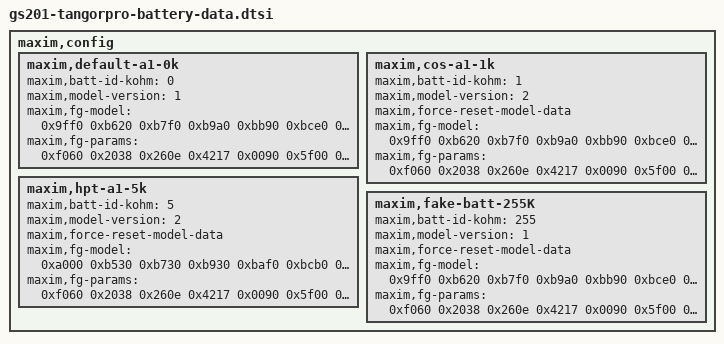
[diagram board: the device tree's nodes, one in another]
// SPDX-License-Identifier: GPL-2.0-only
/*
 * Battery device tree entries
 *
 * Copyright 2022 Google LLC
 *
 */

maxim,config {
	maxim,default-a1-0k {
		maxim,batt-id-kohm = <0>;
		maxim,model-version = <1>;
		maxim,fg-model = /bits/ 16 <
			0x9ff0 0xb620 0xb7f0 0xb9a0 0xbb90 0xbce0 0xbe00 0xbf70
			0xc000 0xc0c0 0xc3c0 0xc710 0xca60 0xcd90 0xd420 0xda20
			0x0080 0x0d40 0x0e00 0x0e10 0x12e0 0x1a40 0x1470 0x16b0
			0x11c0 0x0a80 0x0840 0x08a0 0x08c0 0x06f0 0x0720 0x0720
			0x0200 0x0200 0x0200 0x0200 0x0200 0x0200 0x0200 0x0200
			0x0200 0x0200 0x0200 0x0200 0x0200 0x0200 0x0200 0x0200
		>;
		maxim,fg-params = /bits/ 16 <
			/* 0x0036 */	0xf060	/* IAvgEmpty */
			/* 0x002a */	0x2038	/* RelaxCFG */
			/* 0x0028 */	0x260e	/* LearnCFG */
			/* 0x001D */	0x4217	/* Config */
			/* 0x00BB */	0x0090	/* Config2 */
			/* 0x0013 */	0x5f00	/* FullSOCthr */
			/* 0x0035 */	0x0dcc	/* FullCAPRep */
			/* 0x0018 */	0x0dcc	/* DesignCap */
			/* 0x0046 */	0x3200	/* dPacc */
			/* 0x0045 */	0x0373	/* dQacc */
			/* 0x0023 */	0x0dcc	/* FullCAPNom */
			/* 0x003A */	0xa05f	/* V_empty */
			/* 0x0012 */	0x0f00	/* QResidual00 */
			/* 0x0022 */	0x0780	/* QResidual10 */
			/* 0x0032 */	0x0400	/* QResidual20 */
			/* 0x0042 */	0x0280	/* QResidual30 */
			/* 0x0038 */	0x06c0	/* RCOMP0 */
			/* 0x0039 */	0x1102	/* TempCo */
			/* 0x001E */	0x0463	/* ICHGTerm */
			/* 0x002C */	0xEE0C	/* TGain */
			/* 0x002D */	0x1DF9	/* TOff */
			/* 0x00B9 */	0x0012	/* Curve */
			/* 0x002B */	0x3830	/* MiscCFG */
			/* 0x0004 */	0x1900	/* AtRate */
			/* 0x0049 */	0x2441	/* convgcfg */
			/* 0x0029 */	0xc623	/* FilterCFG */
			/* 0x003c */	0x2D00	/* TaskPeriod */
		>;
	};

	/* 3125_1_101421_RC2_send.002.raw.model.ini.txt http://b/231675666#comment9 */
	/* change MiscCFG https://b/309375239#comment6 */
	maxim,cos-a1-1k {
		maxim,batt-id-kohm = <1>;
		maxim,model-version = <2>;
		maxim,force-reset-model-data;
		maxim,fg-model = /bits/ 16 <
			0x9ff0 0xb620 0xb7f0 0xb9a0 0xbb90 0xbce0 0xbe00 0xbf70
			0xc000 0xc0c0 0xc3c0 0xc710 0xca60 0xcd90 0xd420 0xda20
			0x0080 0x0d40 0x0e00 0x0e10 0x12e0 0x1a40 0x1470 0x16b0
			0x11c0 0x0a80 0x0840 0x08a0 0x08c0 0x06f0 0x0720 0x0720
			0x0200 0x0200 0x0200 0x0200 0x0200 0x0200 0x0200 0x0200
			0x0200 0x0200 0x0200 0x0200 0x0200 0x0200 0x0200 0x0200
		>;
		maxim,fg-params = /bits/ 16 <
			/* 0x0036 */	0xf060	/* IAvgEmpty */
			/* 0x002a */	0x2038	/* RelaxCFG */
			/* 0x0028 */	0x260e	/* LearnCFG */
			/* 0x001D */	0x4217	/* Config */
			/* 0x00BB */	0x0090	/* Config2 */
			/* 0x0013 */	0x5f00	/* FullSOCthr */
			/* 0x0035 */	0x0dcc	/* FullCAPRep */
			/* 0x0018 */	0x0dcc	/* DesignCap */
			/* 0x0046 */	0x3200	/* dPacc */
			/* 0x0045 */	0x0373	/* dQacc */
			/* 0x0023 */	0x0dcc	/* FullCAPNom */
			/* 0x003A */	0xa05f	/* V_empty */
			/* 0x0012 */	0x0f00	/* QResidual00 */
			/* 0x0022 */	0x0780	/* QResidual10 */
			/* 0x0032 */	0x0400	/* QResidual20 */
			/* 0x0042 */	0x0280	/* QResidual30 */
			/* 0x0038 */	0x06c0	/* RCOMP0 */
			/* 0x0039 */	0x1102	/* TempCo */
			/* 0x001E */	0x0463	/* ICHGTerm */
			/* 0x002C */	0xEE0C	/* TGain */
			/* 0x002D */	0x1DF9	/* TOff */
			/* 0x00B9 */	0x0012	/* Curve */
			/* 0x002B */	0x3870	/* MiscCFG */
			/* 0x0004 */	0x1900	/* AtRate */
			/* 0x0049 */	0x2441	/* convgcfg */
			/* 0x0029 */	0xc623	/* FilterCFG */
			/* 0x003c */	0x2D00	/* TaskPeriod */
		>;
	};

	/* 3242_2_040722_RC2_send.048.raw.model.ini.txt http://b/231675666#comment9 */
	/* change MiscCFG https://b/309375239#comment6 */
	maxim,hpt-a1-5k {
		maxim,batt-id-kohm = <5>;
		maxim,model-version = <2>;
		maxim,force-reset-model-data;
		maxim,fg-model = /bits/ 16 <
			0xa000 0xb530 0xb730 0xb930 0xbaf0 0xbcb0 0xbd50 0xbea0
			0xc0c0 0xc240 0xc550 0xc830 0xce00 0xd130 0xd490 0xdad0
			0x0050 0x09b0 0x0b20 0x0fe0 0x1000 0x1ae0 0x15f0 0x11d0
			0x0fe0 0x07d0 0x0880 0x07f0 0x07a0 0x06a0 0x0780 0x0780
			0x0200 0x0200 0x0200 0x0200 0x0200 0x0200 0x0200 0x0200
			0x0200 0x0200 0x0200 0x0200 0x0200 0x0200 0x0200 0x0200
		>;
		maxim,fg-params = /bits/ 16 <
			/* 0x0036 */	0xf060	/* IAvgEmpty */
			/* 0x002a */	0x2038	/* RelaxCFG */
			/* 0x0028 */	0x260e	/* LearnCFG */
			/* 0x001D */	0x4217	/* Config */
			/* 0x00BB */	0x0090	/* Config2 */
			/* 0x0013 */	0x5f00	/* FullSOCthr */
			/* 0x0035 */	0x0de2	/* FullCAPRep */
			/* 0x0018 */	0x0de2	/* DesignCap */
			/* 0x0046 */	0x3200	/* dPacc */
			/* 0x0045 */	0x0378	/* dQacc */
			/* 0x0023 */	0x0de2	/* FullCAPNom */
			/* 0x003A */	0xa05f	/* V_empty */
			/* 0x0012 */	0x1780	/* QResidual00 */
			/* 0x0022 */	0x0a80	/* QResidual10 */
			/* 0x0032 */	0x0400	/* QResidual20 */
			/* 0x0042 */	0x0400	/* QResidual30 */
			/* 0x0038 */	0x0760	/* RCOMP0 */
			/* 0x0039 */	0x0a02	/* TempCo */
			/* 0x001E */	0x0463	/* ICHGTerm */
			/* 0x002C */	0xEE0C	/* TGain */
			/* 0x002D */	0x1DF9	/* TOff */
			/* 0x00B9 */	0x0012	/* Curve */
			/* 0x002B */	0x3870	/* MiscCFG */
			/* 0x0004 */	0x1900	/* AtRate */
			/* 0x0049 */	0x2441	/* convgcfg */
			/* 0x0029 */	0xc623	/* FilterCFG */
			/* 0x003c */	0x2D00	/* TaskPeriod */
		>;
	};

	/* for fake battery: 0xFF http://b/201018651#comment13 */
	maxim,fake-batt-255K {
		maxim,batt-id-kohm = <255>;
		maxim,model-version = <1>;
		maxim,force-reset-model-data;
		maxim,fg-model = /bits/ 16 <
			0x9ff0 0xb620 0xb7f0 0xb9a0 0xbb90 0xbce0 0xbe00 0xbf70
			0xc000 0xc0c0 0xc3c0 0xc710 0xca60 0xcd90 0xd420 0xda20
			0x0080 0x0d40 0x0e00 0x0e10 0x12e0 0x1a40 0x1470 0x16b0
			0x11c0 0x0a80 0x0840 0x08a0 0x08c0 0x06f0 0x0720 0x0720
			0x0200 0x0200 0x0200 0x0200 0x0200 0x0200 0x0200 0x0200
			0x0200 0x0200 0x0200 0x0200 0x0200 0x0200 0x0200 0x0200
		>;
		maxim,fg-params = /bits/ 16 <
			/* 0x0036 */	0xf060	/* IAvgEmpty */
			/* 0x002a */	0x2038	/* RelaxCFG */
			/* 0x0028 */	0x260e	/* LearnCFG */
			/* 0x001D */	0x4217	/* Config */
			/* 0x00BB */	0x0090	/* Config2 */
			/* 0x0013 */	0x5f00	/* FullSOCthr */
			/* 0x0035 */	0x0dcc	/* FullCAPRep */
			/* 0x0018 */	0x0dcc	/* DesignCap */
			/* 0x0046 */	0x3200	/* dPacc */
			/* 0x0045 */	0x0373	/* dQacc */
			/* 0x0023 */	0x0dcc	/* FullCAPNom */
			/* 0x003A */	0xa05f	/* V_empty */
			/* 0x0012 */	0x0f00	/* QResidual00 */
			/* 0x0022 */	0x0780	/* QResidual10 */
			/* 0x0032 */	0x0400	/* QResidual20 */
			/* 0x0042 */	0x0280	/* QResidual30 */
			/* 0x0038 */	0x06c0	/* RCOMP0 */
			/* 0x0039 */	0x1102	/* TempCo */
			/* 0x001E */	0x0463	/* ICHGTerm */
			/* 0x002C */	0xEE0C	/* TGain */
			/* 0x002D */	0x1DF9	/* TOff */
			/* 0x00B9 */	0x0012	/* Curve */
			/* 0x002B */	0x3830	/* MiscCFG */
			/* 0x0004 */	0x1900	/* AtRate */
			/* 0x0049 */	0x2441	/* convgcfg */
			/* 0x0029 */	0xc623	/* FilterCFG */
			/* 0x003c */	0x2D00	/* TaskPeriod */
		>;
	};

};
